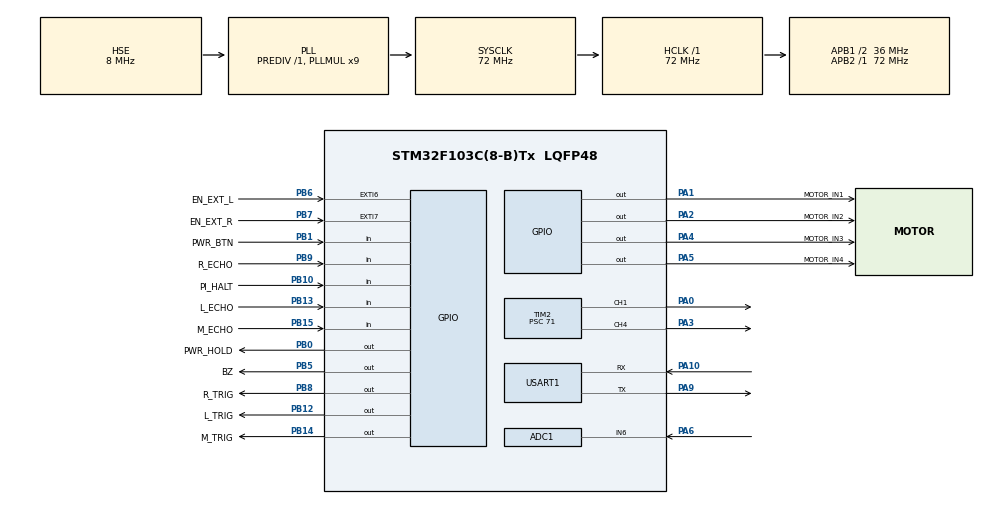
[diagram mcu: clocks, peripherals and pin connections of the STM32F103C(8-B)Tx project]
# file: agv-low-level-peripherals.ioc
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ADC1.Channel-0\#ChannelRegularConversion=ADC_CHANNEL_6
ADC1.NbrOfConversionFlag=1
ADC1.Rank-0\#ChannelRegularConversion=1
ADC1.SamplingTime-0\#ChannelRegularConversion=ADC_SAMPLETIME_239CYCLES_5
ADC1.master=1
Mcu.Family=STM32F1
Mcu.Name=STM32F103C(8-B)Tx
Mcu.Package=LQFP48
NVIC.EXTI9_5_IRQn=true\:0\:0\:false\:false\:true\:true\:true
NVIC.PriorityGroup=NVIC_PRIORITYGROUP_4
PA0-WKUP.Signal=S_TIM2_CH1_ETR
PA1.GPIO_Label=MOTOR_IN1
PA1.Signal=GPIO_Output
PA10.Mode=Asynchronous
PA10.Signal=USART1_RX
PA13.Mode=Serial_Wire
PA13.Signal=SYS_JTMS-SWDIO
PA14.Mode=Serial_Wire
PA14.Signal=SYS_JTCK-SWCLK
PA2.GPIO_Label=MOTOR_IN2
PA2.Signal=GPIO_Output
PA3.Signal=S_TIM2_CH4
PA4.GPIO_Label=MOTOR_IN3
PA4.Signal=GPIO_Output
PA5.GPIO_Label=MOTOR_IN4
PA5.Signal=GPIO_Output
PA6.Signal=ADCx_IN6
PA9.Mode=Asynchronous
PA9.Signal=USART1_TX
PB0.GPIO_Label=PWR_HOLD
PB0.PinState=GPIO_PIN_SET
PB0.Signal=GPIO_Output
PB1.GPIO_Label=PWR_BTN
PB1.GPIO_PuPd=GPIO_PULLUP
PB1.Signal=GPIO_Input
PB10.GPIO_Label=PI_HALT
PB10.GPIO_PuPd=GPIO_PULLDOWN
PB10.Signal=GPIO_Input
PB12.GPIO_Label=L_TRIG
PB12.Signal=GPIO_Output
PB13.GPIO_Label=L_ECHO
PB13.Signal=GPIO_Input
PB14.GPIO_Label=M_TRIG
PB14.Signal=GPIO_Output
PB15.GPIO_Label=M_ECHO
PB15.Signal=GPIO_Input
PB5.GPIO_Label=BZ
PB5.Signal=GPIO_Output
PB6.GPIO_Label=EN_EXT_L
PB6.GPIO_PuPd=GPIO_PULLUP
PB6.Signal=GPXTI6
PB7.GPIO_Label=EN_EXT_R
PB7.GPIO_PuPd=GPIO_PULLUP
PB7.Signal=GPXTI7
PB8.GPIO_Label=R_TRIG
PB8.Signal=GPIO_Output
PB9.GPIO_Label=R_ECHO
PB9.Signal=GPIO_Input
PD0-OSC_IN.Mode=HSE-External-Oscillator
PD0-OSC_IN.Signal=RCC_OSC_IN
PD1-OSC_OUT.Mode=HSE-External-Oscillator
PD1-OSC_OUT.Signal=RCC_OSC_OUT
ProjectManager.HeapSize=0x200
ProjectManager.StackSize=0x400
ProjectManager.TargetToolchain=STM32CubeIDE
RCC.ADCPresc=RCC_ADCPCLK2_DIV6
RCC.AHBFreq_Value=72000000
RCC.APB1CLKDivider=RCC_HCLK_DIV2
RCC.APB1Freq_Value=36000000
RCC.APB1TimFreq_Value=72000000
RCC.APB2Freq_Value=72000000
RCC.APB2TimFreq_Value=72000000
RCC.HCLKFreq_Value=72000000
RCC.PLLMUL=RCC_PLL_MUL9
RCC.PLLSourceVirtual=RCC_PLLSOURCE_HSE
RCC.SYSCLKFreq_VALUE=72000000
RCC.SYSCLKSource=RCC_SYSCLKSOURCE_PLLCLK
RCC.USBFreq_Value=72000000
SH.ADCx_IN6.0=ADC1_IN6,IN6
SH.S_TIM2_CH1_ETR.0=TIM2_CH1,PWM Generation1 CH1
SH.S_TIM2_CH4.0=TIM2_CH4,PWM Generation4 CH4
TIM2.Channel-PWM\ Generation1\ CH1=TIM_CHANNEL_1
TIM2.Channel-PWM\ Generation4\ CH4=TIM_CHANNEL_4
TIM2.Period=999
TIM2.Prescaler=71
USART1.VirtualMode=VM_ASYNC
VP_TIM2_VS_ClockSourceINT.Mode=Internal
board=custom

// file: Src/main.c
/* USER CODE BEGIN Header */
/**
  ******************************************************************************
  * @file           : main.c
  * @brief          : Main program body
  ******************************************************************************
  * @attention
  *
  * <h2><center>&copy; Copyright (c) 2026 STMicroelectronics.
  * All rights reserved.</center></h2>
  *
  * This software component is licensed by ST under BSD 3-Clause license,
  * the "License"; You may not use this file except in compliance with the
  * License. You may obtain a copy of the License at:
  *                        opensource.org/licenses/BSD-3-Clause
  *
  ******************************************************************************
  */
/* USER CODE END Header */

#include "main.h"
#include "adc.h"
#include "tim.h"
#include "usart.h"
#include "gpio.h"

/* USER CODE BEGIN Includes */
#include "amr_app.h"
/* USER CODE END Includes */

void SystemClock_Config(void);

int main(void)
{

  /* MCU Configuration--------------------------------------------------------*/

  /* Reset of all peripherals, Initializes the Flash interface and the Systick. */
  HAL_Init();

  /* Configure the system clock */
  SystemClock_Config();

  /* Initialize all configured peripherals */
  MX_GPIO_Init();
  MX_ADC1_Init();
  MX_TIM2_Init();
  MX_USART1_UART_Init();
  /* USER CODE BEGIN 2 */
  /* Khoi tao toan bo he thong Firmware AGV Giai doan 1 */
  AMR_App_Init();
  /* USER CODE END 2 */

  /* Infinite loop */
  /* USER CODE BEGIN WHILE */
  while (1)
  {
    /* Vong lap hop tac (Cooperative Super-Loop): Sonar TDM, Motor Ramp, ADC Pin, Stall, Power */
    AMR_App_Loop();
    /* USER CODE END WHILE */

  }
}

void SystemClock_Config(void)
{
  RCC_OscInitTypeDef RCC_OscInitStruct = {0};
  RCC_ClkInitTypeDef RCC_ClkInitStruct = {0};
  RCC_PeriphCLKInitTypeDef PeriphClkInit = {0};

  /** Initializes the CPU, AHB and APB busses clocks
  */
  RCC_OscInitStruct.OscillatorType = RCC_OSCILLATORTYPE_HSE;
  RCC_OscInitStruct.HSEState = RCC_HSE_ON;
  RCC_OscInitStruct.HSEPredivValue = RCC_HSE_PREDIV_DIV1;
  RCC_OscInitStruct.HSIState = RCC_HSI_ON;
  RCC_OscInitStruct.PLL.PLLState = RCC_PLL_ON;
  RCC_OscInitStruct.PLL.PLLSource = RCC_PLLSOURCE_HSE;
  RCC_OscInitStruct.PLL.PLLMUL = RCC_PLL_MUL9;
  if (HAL_RCC_OscConfig(&RCC_OscInitStruct) != HAL_OK)
  {
    Error_Handler();
  }
  /** Initializes the CPU, AHB and APB busses clocks
  */
  RCC_ClkInitStruct.ClockType = RCC_CLOCKTYPE_HCLK|RCC_CLOCKTYPE_SYSCLK
                              |RCC_CLOCKTYPE_PCLK1|RCC_CLOCKTYPE_PCLK2;
  RCC_ClkInitStruct.SYSCLKSource = RCC_SYSCLKSOURCE_PLLCLK;
  RCC_ClkInitStruct.AHBCLKDivider = RCC_SYSCLK_DIV1;
  RCC_ClkInitStruct.APB1CLKDivider = RCC_HCLK_DIV2;
  RCC_ClkInitStruct.APB2CLKDivider = RCC_HCLK_DIV1;

  if (HAL_RCC_ClockConfig(&RCC_ClkInitStruct, FLASH_LATENCY_2) != HAL_OK)
  {
    Error_Handler();
  }
  PeriphClkInit.PeriphClockSelection = RCC_PERIPHCLK_ADC;
  PeriphClkInit.AdcClockSelection = RCC_ADCPCLK2_DIV6;
  if (HAL_RCCEx_PeriphCLKConfig(&PeriphClkInit) != HAL_OK)
  {
    Error_Handler();
  }
}

void Error_Handler(void)
{
}

/************************ (C) COPYRIGHT STMicroelectronics *****END OF FILE****/
